VERSION "HIPBNYYYYYYYYYYYYYYYYYYYYYYYYYYYYYYYYYYYYY/4/%%%/4/'%**4YYY///"

NS_ :

BS_:

BU_:

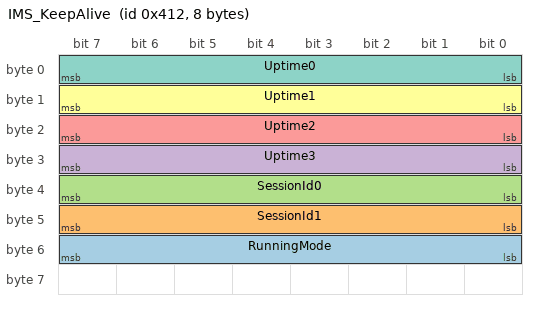
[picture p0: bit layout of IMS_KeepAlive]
BO_ 1042 IMS_KeepAlive: 8 Vector__XXX
 SG_ RunningMode : 48|8@1+ (1,0) [0|255] "" Vector__XXX
 SG_ SessionId1 : 40|8@1+ (1,0) [0|255] "" Vector__XXX
 SG_ SessionId0 : 32|8@1+ (1,0) [0|255] "" Vector__XXX
 SG_ Uptime3 : 24|8@1+ (1,0) [0|255] "" Vector__XXX
 SG_ Uptime2 : 16|8@1+ (1,0) [0|255] "" Vector__XXX
 SG_ Uptime1 : 8|8@1+ (1,0) [0|255] "" Vector__XXX
 SG_ Uptime0 : 0|8@1+ (1,0) [0|255] "" Vector__XXX

BA_DEF_  "BusType" STRING ;
BA_DEF_DEF_  "BusType" "CAN";
